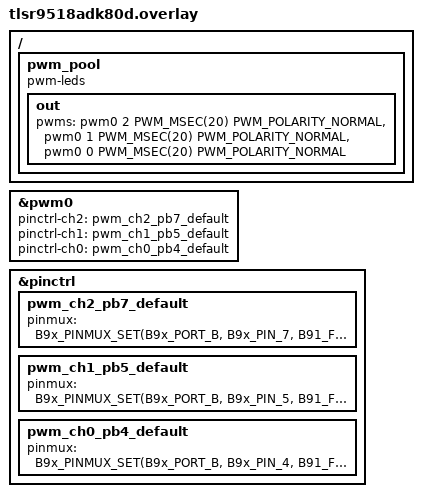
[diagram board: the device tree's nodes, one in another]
/*
 * Copyright (c) 2024 Telink Semiconductor
 *
 * SPDX-License-Identifier: Apache-2.0
 */

/*
 * Copyright (c) 2024 Telink Semiconductor
 *
 * SPDX-License-Identifier: Apache-2.0
 */

/ {
	pwm_pool {
		compatible = "pwm-leds";
		out {
			pwms = <&pwm0 2 PWM_MSEC(20) PWM_POLARITY_NORMAL>,
					<&pwm0 1 PWM_MSEC(20) PWM_POLARITY_NORMAL>,
					<&pwm0 0 PWM_MSEC(20) PWM_POLARITY_NORMAL>;
		};
	};
};

&pwm0 {
	/* On board RGB LEDs */
	pinctrl-ch2 = <&pwm_ch2_pb7_default>;
	pinctrl-ch1 = <&pwm_ch1_pb5_default>;
	pinctrl-ch0 = <&pwm_ch0_pb4_default>;
};

&pinctrl {
	pwm_ch2_pb7_default: pwm_ch2_pb7_default {
		pinmux = <B9x_PINMUX_SET(B9x_PORT_B, B9x_PIN_7, B91_FUNC_A)>;
	};
	pwm_ch1_pb5_default: pwm_ch1_pb5_default {
		pinmux = <B9x_PINMUX_SET(B9x_PORT_B, B9x_PIN_5, B91_FUNC_C)>;
	};
	pwm_ch0_pb4_default: pwm_ch0_pb4_default {
		pinmux = <B9x_PINMUX_SET(B9x_PORT_B, B9x_PIN_4, B91_FUNC_B)>;
	};
};
